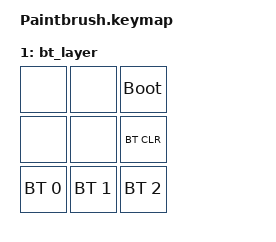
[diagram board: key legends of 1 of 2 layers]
#include <behaviors.dtsi>
#include <dt-bindings/zmk/keys.h>
#include <dt-bindings/zmk/bt.h>

/ {
    keymap {
        compatible = "zmk,keymap";

        default_layer {
            bindings = <
                &kp KP_N7    &kp KP_N8    &kp KP_N9    &kp KP_N0
                &kp KP_N4    &kp KP_N5    &kp KP_N6    &kp KP_ENTER
            >;
        };

        bt_layer {
            bindings = <
                &none       &none       &bootloader
                &none       &none       &bt BT_CLR
                &bt BT_SEL 0    &bt BT_SEL 1    &bt BT_SEL 2
            >;
        };
    };
};
